# f29h85x_outputxbar_regs register map
Vendor: Texas Instruments
Peripheral module from a debugger description file (folder C29).
Registers are 32-bit, read-write, no defined reset value unless marked. A register's access mark holds for its fields unless they carry their own. Offsets are as the file gives them; lines under a group give offsets from that group; [hi:lo] are bit positions; {n}, {i} and the like mark numbered series; 'fields as' and 'values as' point back to an identical list; <NAME> marks a mode.

## OUTPUTXBAR_REGS — OUTPUTXBAR Registers
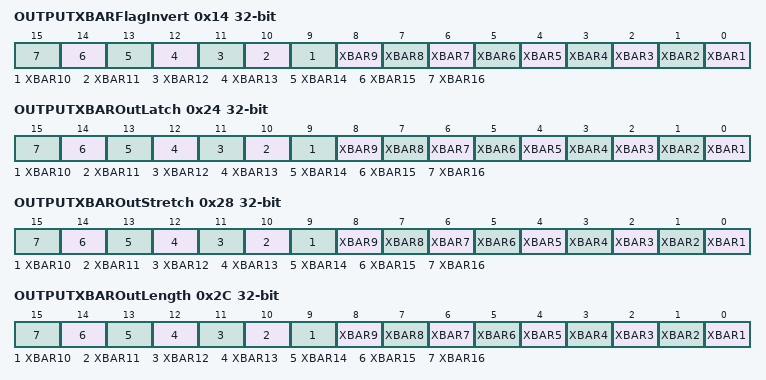
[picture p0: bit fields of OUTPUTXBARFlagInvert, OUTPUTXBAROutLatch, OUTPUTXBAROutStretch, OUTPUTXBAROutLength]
0x14 OUTPUTXBARFlagInvert — Output Signal inversion register
  [n-1] XBAR{n} (n=1..16) — Invert XBAR Output Before Latch for XBAR{n}
0x24 OUTPUTXBAROutLatch — Output Signal Select Latch
  [n-1] XBAR{n} (n=1..16) — XBAR Output Latch Select for XBAR{n}
0x28 OUTPUTXBAROutStretch — Output Signal Stretched Pulse Version Select
  [n-1] XBAR{n} (n=1..16) — XBAR Output Stretch Select for XBAR{n}
0x2C OUTPUTXBAROutLength — Output Signal Stretched Pulse Length Select
  [n-1] XBAR{n} (n=1..16) — XBAR Output Stretch Length Select for XBAR{n}
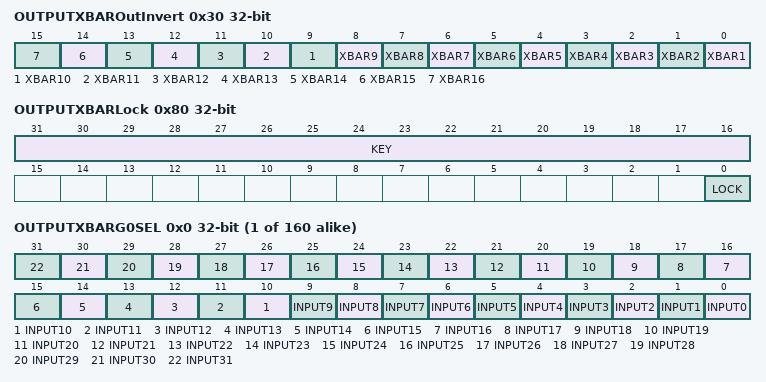
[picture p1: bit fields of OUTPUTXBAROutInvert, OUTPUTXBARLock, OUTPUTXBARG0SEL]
0x30 OUTPUTXBAROutInvert — Output Signal Invert Select
  [n-1] XBAR{n} (n=1..16) — Invert XBAR Output for XBAR{n}
0x80 OUTPUTXBARLock — Configuration Lock register
  [31:16] KEY — Write protection KEY
  [0] LOCK — Locks the configuration for EOUTPUT-XBAR
{0x100+0x40*i} OUTPUTXBAR_REGS_RegisterFile0[{i}] (i=0..15) group
  {0x0+4j} OUTPUTXBARG{j}SEL (j=0..9) — OUTPUTXBAR G{j} Input Select
    [n] INPUT{n} (n=0..31) — Select bit for INPUT{n}
